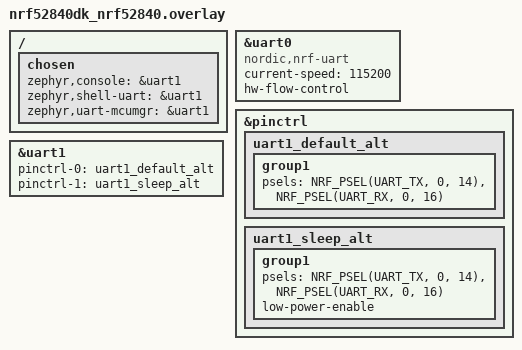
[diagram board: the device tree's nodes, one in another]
/* SPDX-License-Identifier: Apache-2.0 */

/ {
	chosen {
		zephyr,console = &uart1;
		zephyr,shell-uart = &uart1;
		zephyr,uart-mcumgr = &uart1;
	};
};

&uart0 {
	compatible = "nordic,nrf-uart";
	current-speed = <115200>;
	status = "okay";
	hw-flow-control;
};

&pinctrl {
   uart1_default_alt: uart1_default_alt {
      group1 {
         psels = <NRF_PSEL(UART_TX, 0, 14)>,
                 <NRF_PSEL(UART_RX, 0, 16)>;
      };
   };
   /* required if CONFIG_PM_DEVICE=y */
   uart1_sleep_alt: uart1_sleep_alt {
      group1 {
         psels = <NRF_PSEL(UART_TX, 0, 14)>,
                 <NRF_PSEL(UART_RX, 0, 16)>;
         low-power-enable;
      };
   };
};

&uart1 {
  status = "okay";
  pinctrl-0 = <&uart1_default_alt>;
  /* if sleep state is not used, use /delete-property/ pinctrl-1; and
   * skip the "sleep" entry.
   */
  pinctrl-1 = <&uart1_sleep_alt>;
  pinctrl-names = "default", "sleep";
};
